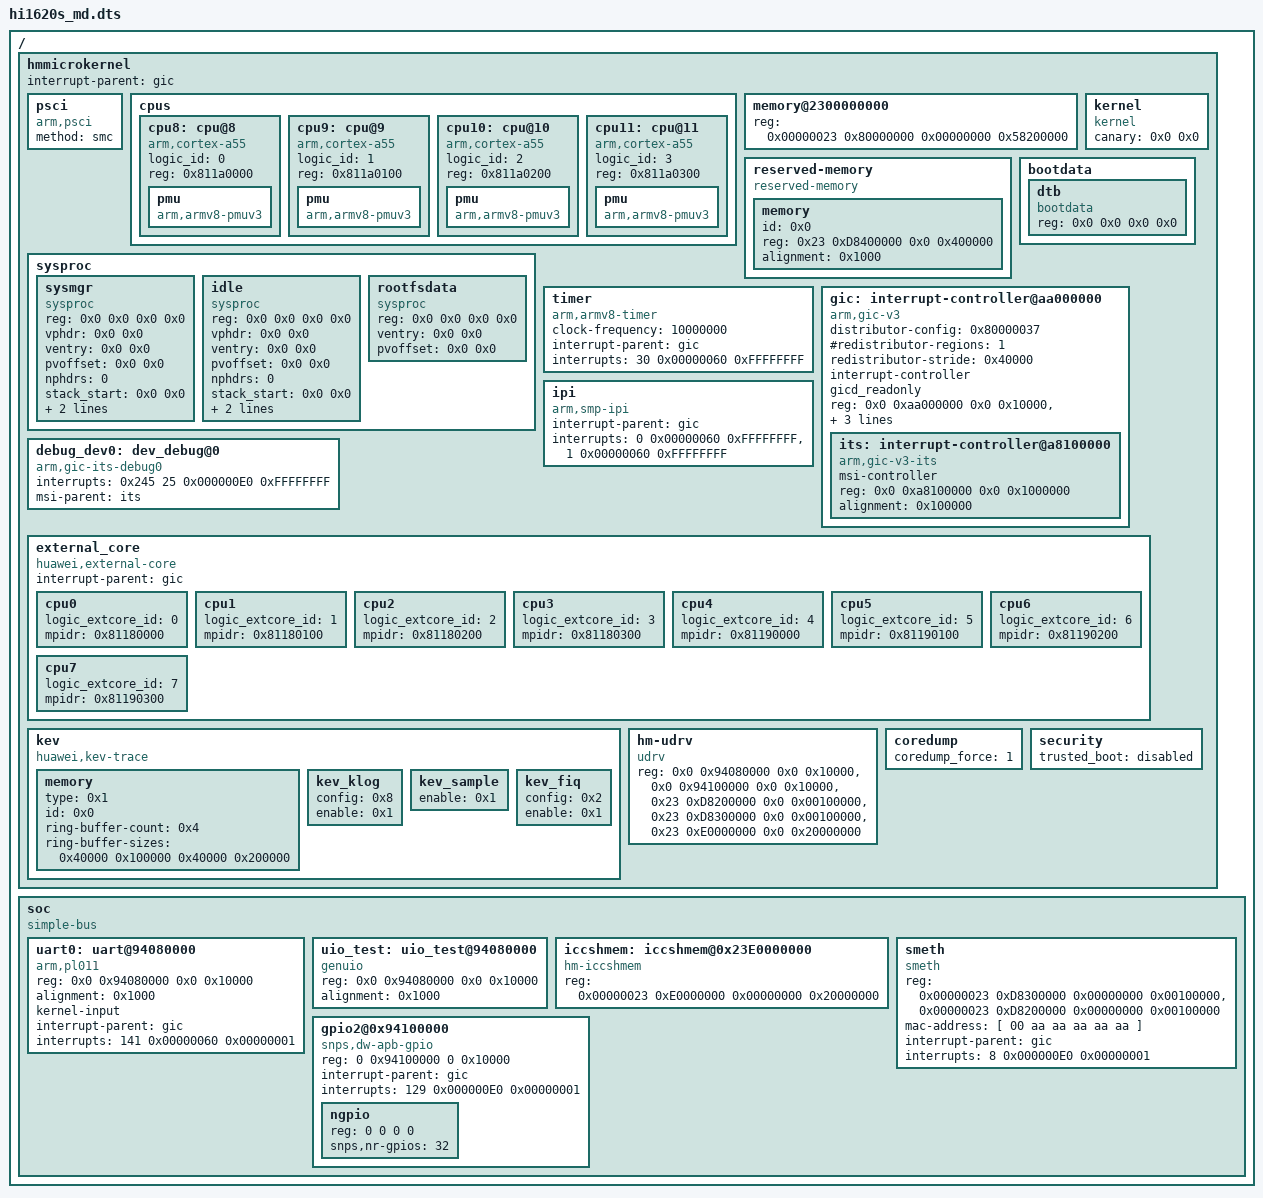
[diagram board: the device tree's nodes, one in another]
/dts-v1/;
/ { #address-cells = <2>; #size-cells = <2>; hmmicrokernel {
	interrupt-parent = <&gic>;
	#address-cells = <2>;
	#size-cells = <2>;

	psci {
		compatible = "arm,psci";
		method = "smc";
	};

	cpus {
		#address-cells = <1>;
		#size-cells = <0>;
//		cpu0:  cpu@0  { compatible = "arm,cortex-a55", "arm,armv8"; device_type = "cpu"; logic_id = <0>;  reg = <0x81180000>; pmu { compatible = "arm,armv8-pmuv3"; }; };
//		cpu1:  cpu@1  { compatible = "arm,cortex-a55", "arm,armv8"; device_type = "cpu"; logic_id = <1>;  reg = <0x81180100>; pmu { compatible = "arm,armv8-pmuv3"; }; };
//		cpu2:  cpu@2  { compatible = "arm,cortex-a55", "arm,armv8"; device_type = "cpu"; logic_id = <2>;  reg = <0x81180200>; pmu { compatible = "arm,armv8-pmuv3"; }; };
//		cpu3:  cpu@3  { compatible = "arm,cortex-a55", "arm,armv8"; device_type = "cpu"; logic_id = <3>;  reg = <0x81180300>; pmu { compatible = "arm,armv8-pmuv3"; }; };
//		cpu4:  cpu@4  { compatible = "arm,cortex-a55", "arm,armv8"; device_type = "cpu"; logic_id = <4>;  reg = <0x81190000>; pmu { compatible = "arm,armv8-pmuv3"; }; };
//		cpu5:  cpu@5  { compatible = "arm,cortex-a55", "arm,armv8"; device_type = "cpu"; logic_id = <5>;  reg = <0x81190100>; pmu { compatible = "arm,armv8-pmuv3"; }; };
//		cpu6:  cpu@6  { compatible = "arm,cortex-a55", "arm,armv8"; device_type = "cpu"; logic_id = <6>;  reg = <0x81190200>; pmu { compatible = "arm,armv8-pmuv3"; }; };
//		cpu7:  cpu@7  { compatible = "arm,cortex-a55", "arm,armv8"; device_type = "cpu"; logic_id = <7>;  reg = <0x81190300>; pmu { compatible = "arm,armv8-pmuv3"; }; };
		cpu8:  cpu@8  { compatible = "arm,cortex-a55", "arm,armv8"; device_type = "cpu"; logic_id = <0>;  reg = <0x811a0000>; pmu { compatible = "arm,armv8-pmuv3"; }; };
		cpu9:  cpu@9  { compatible = "arm,cortex-a55", "arm,armv8"; device_type = "cpu"; logic_id = <1>;  reg = <0x811a0100>; pmu { compatible = "arm,armv8-pmuv3"; }; };
		cpu10: cpu@10 { compatible = "arm,cortex-a55", "arm,armv8"; device_type = "cpu"; logic_id = <2>;  reg = <0x811a0200>; pmu { compatible = "arm,armv8-pmuv3"; }; };
		cpu11: cpu@11 { compatible = "arm,cortex-a55", "arm,armv8"; device_type = "cpu"; logic_id = <3>;  reg = <0x811a0300>; pmu { compatible = "arm,armv8-pmuv3"; }; };
//		cpu12: cpu@12 { compatible = "arm,cortex-a55", "arm,armv8"; device_type = "cpu"; logic_id = <12>; reg = <0x811b0000>; pmu { compatible = "arm,armv8-pmuv3"; }; };
//		cpu13: cpu@13 { compatible = "arm,cortex-a55", "arm,armv8"; device_type = "cpu"; logic_id = <13>; reg = <0x811b0100>; pmu { compatible = "arm,armv8-pmuv3"; }; };
//		cpu14: cpu@14 { compatible = "arm,cortex-a55", "arm,armv8"; device_type = "cpu"; logic_id = <14>; reg = <0x811b0200>; pmu { compatible = "arm,armv8-pmuv3"; }; };
//		cpu15: cpu@15 { compatible = "arm,cortex-a55", "arm,armv8"; device_type = "cpu"; logic_id = <15>; reg = <0x811b0300>; pmu { compatible = "arm,armv8-pmuv3"; }; };
//		cpu16: cpu@16 { compatible = "arm,cortex-a55", "arm,armv8"; device_type = "cpu"; logic_id = <16>; reg = <0x811c0000>; pmu { compatible = "arm,armv8-pmuv3"; }; };
//		cpu17: cpu@17 { compatible = "arm,cortex-a55", "arm,armv8"; device_type = "cpu"; logic_id = <17>; reg = <0x811c0100>; pmu { compatible = "arm,armv8-pmuv3"; }; };
//		cpu18: cpu@18 { compatible = "arm,cortex-a55", "arm,armv8"; device_type = "cpu"; logic_id = <18>; reg = <0x811c0200>; pmu { compatible = "arm,armv8-pmuv3"; }; };
//		cpu19: cpu@19 { compatible = "arm,cortex-a55", "arm,armv8"; device_type = "cpu"; logic_id = <19>; reg = <0x811c0300>; pmu { compatible = "arm,armv8-pmuv3"; }; };
//		cpu20: cpu@20 { compatible = "arm,cortex-a55", "arm,armv8"; device_type = "cpu"; logic_id = <20>; reg = <0x811d0000>; pmu { compatible = "arm,armv8-pmuv3"; }; };
//		cpu21: cpu@21 { compatible = "arm,cortex-a55", "arm,armv8"; device_type = "cpu"; logic_id = <21>; reg = <0x811d0100>; pmu { compatible = "arm,armv8-pmuv3"; }; };
//		cpu22: cpu@22 { compatible = "arm,cortex-a55", "arm,armv8"; device_type = "cpu"; logic_id = <22>; reg = <0x811d0200>; pmu { compatible = "arm,armv8-pmuv3"; }; };
//		cpu23: cpu@23 { compatible = "arm,cortex-a55", "arm,armv8"; device_type = "cpu"; logic_id = <23>; reg = <0x811d0300>; pmu { compatible = "arm,armv8-pmuv3"; }; };
	};

	memory@2300000000 {
		device_type = "memory";
		reg = <0x00000023 0x80000000 0x00000000 0x58200000>;
	};

	reserved-memory {
		compatible = "reserved-memory";
		#address-cells = <0x2>;
		#size-cells = <0x2>;
		memory {
			id = <0x0>;
			reg = <0x23 0xD8400000 0x0 0x400000>;
			alignment = <0x1000>;
		};
	};

	sysproc {
		#address-cells = <2>;
		#size-cells = <2>;
		sysmgr {
			compatible = "sysproc", "sysmgr";
			/* filled by bootloader */
			reg      = <0x0 0x0 0x0 0x0>;
			vphdr    = <0x0 0x0>;
			ventry   = <0x0 0x0>;
			pvoffset = <0x0 0x0>;
			nphdrs   = <0>;
			stack_start = <0x0 0x0>;
			stack_end = <0x0 0x0>;
			canary = <0x0 0x0>;
		};
		idle {
			compatible = "sysproc", "idle";
			/* filled by bootloader */
			reg      = <0x0 0x0 0x0 0x0>;
			vphdr    = <0x0 0x0>;
			ventry   = <0x0 0x0>;
			pvoffset = <0x0 0x0>;
			nphdrs   = <0>;
			stack_start = <0x0 0x0>;
			stack_end = <0x0 0x0>;
			canary = <0x0 0x0>;
		};
		rootfsdata {
			compatible = "sysproc", "rootfs";
			/* filled by bootloader */
			reg      = <0x0 0x0 0x0 0x0>;
			ventry   = <0x0 0x0>;
			pvoffset = <0x0 0x0>;
		};

	};

	kernel {
		compatible = "kernel";
		/* filled by bootloader */
		canary = <0x0 0x0>;
	};

	bootdata {
		#address-cells = <2>;
		#size-cells = <2>;
		dtb {
			compatible = "bootdata", "dtb";
			/* filled by bootloader */
			reg = <0x0 0x0 0x0 0x0>;
		};
	};

	timer {
		compatible = "arm,armv8-timer";
		clock-frequency = <10000000>;

		/* interrupt settings */
		interrupt-parent = <&gic>;

		/* PPI 30: Non-secure physical timer
		 * level triggered, hwprio:0x60 */
		interrupts = <30 0x00000060 0xFFFFFFFF>;
	};

	/* See Documentation/dts-gic.md for interrupts and distributor_config */
	gic: interrupt-controller@aa000000 {
		compatible = "arm,gic-v3";

		#address-cells = <2>;
		#size-cells = <2>;

		/* Enable group 0, Group1NS, Group1S, ARE_NS, ARE_S,
		 * Split EOI and Deactive Mode */
		distributor-config = <0x80000037>;

		#interrupt-cells = <3>;
		#redistributor-regions = <1>;
		redistributor-stride = <0x40000>;
		interrupt-controller;
		gicd_readonly;

		reg =	<0x0 0xaa000000 0x0 0x10000>,	/* GICD */
			<0x0 0xaa100000 0x0 0x800000>;	/* GICR */
		alignment = <0x100000 0x100000>;

		interrupts = <25 0x000000E0 0xFFFFFFFF>;

		/* We haven't support this */
		its: interrupt-controller@a8100000 {
			compatible = "arm,gic-v3-its";
			msi-controller;
			reg = <0x0 0xa8100000 0x0 0x1000000>;
			alignment = <0x100000>;
			#interrupt-cells = <4>;
		};
	};

	ipi {
		/* smp ipi */
		compatible = "arm,smp-ipi";

		interrupt-parent = <&gic>;

		/* interrupt settings:
		 * 1st cell: real hardware irq number
		 *     ARM recommendation: ID 0-7 for Non-Secure;
		 *                         ID 8-15 for Secure Interrupt
		 * 2nd cell: interrupt config
		 *     bit [27:26]: Group setting
		 *     bit [24]: Trigger Type
		 *     bit [23:8]: Reserved
		 *     bit [7:0]: Priority
		 * 3rd cell: interrupt target config
		 *     Warning: Send to all cpus by default
		 */
		interrupts =	<0 0x00000060 0xFFFFFFFF>, /* IPI_RESCHEDULE */
				<1 0x00000060 0xFFFFFFFF>; /* IPI_CALL_FUNC */
	};

	/* used to debug its driver */
	debug_dev0:dev_debug@0 {
		compatible = "arm,gic-its-debug0";
		/* devid is 0x245, nr is 25, config is 0x00000002 0xFFFFFFFF */
		interrupts = <0x245 25 0x000000E0 0xFFFFFFFF>;
		msi-parent = <&its>;
	};

	external_core {
		compatible = "huawei,external-core";

		interrupt-parent = <&gic>;

		cpu0 {
			logic_extcore_id = <0>;
			mpidr = <0x81180000>;
		};
		cpu1 {
			logic_extcore_id = <1>;
			mpidr = <0x81180100>;
		};
		cpu2 {
			logic_extcore_id = <2>;
			mpidr = <0x81180200>;
		};
		cpu3 {
			logic_extcore_id = <3>;
			mpidr = <0x81180300>;
		};
		cpu4 {
			logic_extcore_id = <4>;
			mpidr = <0x81190000>;
		};
		cpu5 {
			logic_extcore_id = <5>;
			mpidr = <0x81190100>;
		};
		cpu6 {
			logic_extcore_id = <6>;
			mpidr = <0x81190200>;
		};
		cpu7 {
			logic_extcore_id = <7>;
			mpidr = <0x81190300>;
		};
	};

	kev {
		compatible = "huawei,kev-trace";

		memory {
			type = <0x1>;
			id = <0x0>;
			ring-buffer-count = <0x4>;
			ring-buffer-sizes = <0x40000 0x100000 0x40000 0x200000>;
		};
		kev_klog {
			config = <0x8>;
			enable = <0x1>;
		};
		kev_sample {
			enable = <0x1>;
		};
		kev_fiq {
			config = <0x2>;
			enable = <0x1>;
		};
	};

	hm-udrv {
		compatible = "udrv";
		reg = <0x0 0x94080000 0x0 0x10000>,
		      <0x0 0x94100000 0x0 0x10000>,
		      <0x23 0xD8200000 0x0 0x00100000>,
		      <0x23 0xD8300000 0x0 0x00100000>,
		      <0x23 0xE0000000 0x0 0x20000000>;
	};

	coredump {
		coredump_force = <1>;
	};
	security {
		trusted_boot = "disabled";
	};
	};

	soc {
		compatible = "simple-bus";
		#address-cells = <2>;
		#size-cells = <2>;
		ranges;

		uart0: uart@94080000 {
			compatible = "arm,pl011", "arm,pl011,uart";
			reg = <0x0 0x94080000 0x0 0x10000>;
			alignment = <0x1000>;

			/* kernel control input */
			kernel-input;

			interrupt-parent=<&gic>;
			interrupts=<141 0x00000060 0x00000001>;
		};

		uio_test: uio_test@94080000 {
			compatible = "genuio";
			reg = <0x0 0x94080000 0x0 0x10000>;
			alignment = <0x1000>;
		};

		iccshmem: iccshmem@0x23E0000000 {
			compatible = "hm-iccshmem";
			reg = <0x00000023 0xE0000000 0x00000000 0x20000000>;
		};

		smeth {
			compatible = "smeth";
			reg = <0x00000023 0xD8300000 0x00000000 0x00100000>,
			      <0x00000023 0xD8200000 0x00000000 0x00100000>;
			mac-address = [ 00 aa aa aa aa aa ];
			interrupt-parent=<&gic>;
			interrupts=<8 0x000000E0 0x00000001>;
		};

		gpio2@0x94100000 {
                        compatible = "snps,dw-apb-gpio";
                        reg = <0 0x94100000 0 0x10000>;
                        interrupt-parent = <&gic>;
                        interrupts = <129 0x000000E0 0x00000001>;
                        status = "ok";
                        ngpio {
                                reg = <0 0 0 0>;
                                snps,nr-gpios = <32>;
                        };
                };
	};
};
